# SPI0 register map
Vendor: Texas Instruments
Peripheral module from a debugger description file (folder 66AK2G0x_66AK2G1x).
Registers are 32-bit, access per field, reset 0x0 unless marked. A register's access mark holds for its fields unless they carry their own. Offsets are as the file gives them; lines under a group give offsets from that group; [hi:lo] are bit positions; {n}, {i} and the like mark numbered series; 'fields as' and 'values as' point back to an identical list; <NAME> marks a mode.

## SPI0
0x00 SPIGCR0
  [0] RESET rw — Reset bit for the module. This bit needs to be set to 1 before any operation on SPI can be done.
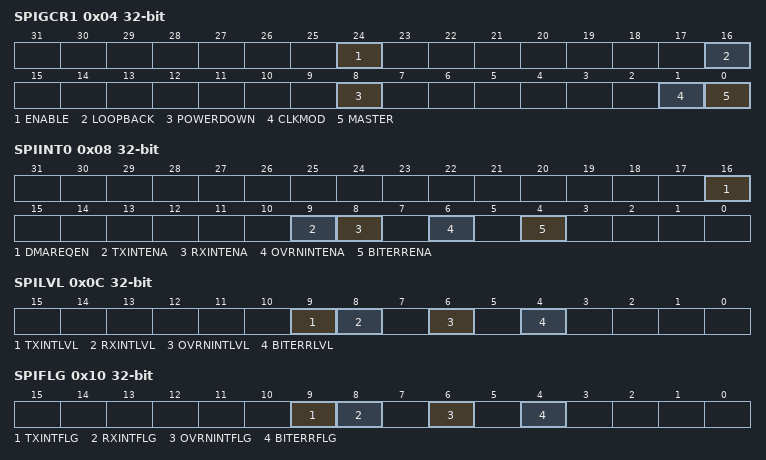
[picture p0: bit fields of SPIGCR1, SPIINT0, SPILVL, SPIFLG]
0x04 SPIGCR1
  [24] ENABLE rw — SPI enable. This bit enables the SPI transfers. The other SPI configuration registers except SPIINT0[16] DMAREQEN bit should be configured before writing 1 to this bit. This will prevent the SPI from responding to bus operations erroneously while it is in the process of being configured. The SPIINT0[16] DMAREQEN bit should be enabled after setting SPIGCR1[24] ENABLE bit. If SPIINT0[16] DMAREQEN bit is enabled before setting SPIGCR1[24] ENABLE bit then the first DMA request that occurs before the SPI is ready for data transfer may get dropped. When
  [16] LOOPBACK rw — Internal loop-back test mode. The internal self-test option can be enabled by setting this bit. If the SPIm_SIMO and SPIm_SOMI pins are configured with SPI functionality, then the SPIm_SIMO pin is internally connected to the SPIm_SOMI pin. The transmit data is looped back as receive data and is stored in the receive field of the concerned buffer. Externally, during loop-back operation, the SPIm_CLK pin outputs an inactive value, SPIm_SIMO and SPIm_SOMI pins remain in high-impedance state. The SPI has to be initialized in master mode before the loop-back can be selected. If the SPI is initialized in slave mode or a data transfer is ongoing, errors may result.
  [8] POWERDOWN rw — When active, the SPI state machine enters a power-down state.
  [1] CLKMOD rw — Clock mode. Selects either an internal or external clock source. This bit also determines the I/O direction of the chip select (SPIm_SCSnx) pins in functional mode.
  [0] MASTER rw — SPIm_SIMO/SPIm_SOMI pin direction determination. Determines the direction of the SPIm_SIMO and SPIm_SOMI pins. This bit determines whether the SPI is in Master mode or Slave mode.
0x08 SPIINT0
  [16] DMAREQEN rw — DMA request enable. Enables the DMA request signal to be generated for both receive and transmit channels. Set SPIINT0[16] DMAREQEN bit only after setting the SPIGCR1[24] ENABLE bit to 1.
  [9] TXINTENA rw — An interrupt is to be generated every time data is written to the shift register, so that a new data can be written to TXBUF. Setting this bit will generate an interrupt if theSPIFLG[9] TXINTFLG bit is set to 1.
  [8] RXINTENA rw — Receive interrupt enable. An interrupt is to be generated when the SPIFLG[8] RXINTFLG bit is set.
  [6] OVRNINTENA rw — Overrun interrupt enable. An interrupt is to be generated when the SPIFLG[6] OVRNINTFLG bit is set.
  [4] BITERRENA rw — Enables interrupt on bit error. An interrupt is to be generated when the SPIFLG[4] BITERRFLG bit is set.
0x0C SPILVL
  [9] TXINTLVL rw — Transmit interrupt level.
  [8] RXINTLVL rw — Receive interrupt level.
  [6] OVRNINTLVL rw — Receive overrun interrupt level.
  [4] BITERRLVL rw — Bit error interrupt level.
0x10 SPIFLG access not given
  [9] TXINTFLG ro — Transmitter empty interrupt flag. Serves as an interrupt flag indicating that the transmit buffer (TXBUF) is empty and a new data can be written to it. This flag is set when a data is copied to the shift register either directly or from the TXBUF register. This bit is cleared by one of following ways:
  [8] RXINTFLG — Receiver full interrupt flag. This flag is set when a word is received and copied into the buffer register (SPIBUF). This bit is cleared under the following ways: (access RW1C)
  [6] OVRNINTFLG — Receiver overrun flag. The bit is set when a receive operation completes before the previous character has been read from the receive buffer. The bit indicates that the last received character has been overwritten and therefore lost. This bit is cleared under the following conditions: (access RW1C)
  [4] BITERRFLG — This bit is set when a mismatch of internal transmit data and transmitted data is detected. The SPI samples the signal of the transmit pin (master: SPIm_SIMO, slave: SPIm_SOMI) at the receive point (half clock cycle after transmit point). If the sampled value differs from the transmitted value a bit error is detected and the flag is set. A possible reason for a bit error can be a too high bit rate/capacitive load or another master/slave trying to transmit at the same time. This flag can be cleared by one of the following ways: (access RW1C)
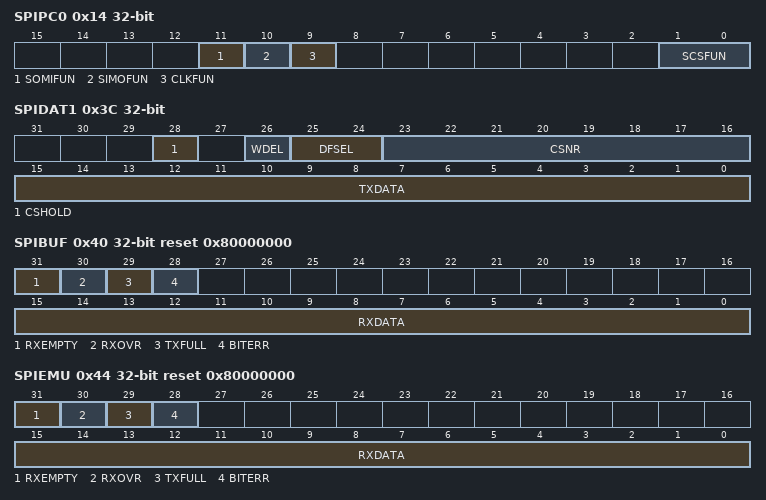
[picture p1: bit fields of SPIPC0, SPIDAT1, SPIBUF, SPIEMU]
0x14 SPIPC0
  [11] SOMIFUN rw — Slave out, master in pin function. This bit determines whether the SPIm_SOMI pin is Reserved or a SPI functional pin.
  [10] SIMOFUN rw — Slave in, master out pin function. This bit determines whether the SPIm_SIMO pin is Reserved or a SPI functional pin.
  [9] CLKFUN rw — SPI clock pin function. This bit determines whether the SPIm_CLK pin is Reserved or a SPI functional pin.
  [1:0] SCSFUN rw — SPI chip select pin function. The bit in this field determines whether the SPIm_SCSnx pin is Reserved or a SPI functional pin. For more information about supported number of the chip select pins, see , SPI Overview.
0x38 SPIDAT0
  [15:0] TXDATA rw — SPI transmit data (value = 0-FFFFh). When written, these bits will be copied to the shift register if it is empty. If the shift register is not empty, the TXBUF will hold the written values. SPIGCR1[24] ENABLE bit must be set to 1 before this register can be written to. Writing a 0 to the SPIGCR1[24] ENABLE bit forces the SPIDAT0[15-0] TXDATA field to 0.
0x3C SPIDAT1
  [28] CSHOLD rw — Chip select hold mode. The SPIDAT1[28] CSHOLD bit is supported in master mode only. In slave mode, this bit is ignored. SPIDAT1[28] CSHOLD bit defines the behavior of the chip select lines at the end of a data transfer.
  [26] WDEL rw — Enable the delay counter at the end of the current transaction. The SPIDAT1[26] WDEL bit is supported in master mode only. In slave mode, this bit is ignored.
  [25:24] DFSEL rw — Data word format select:
  [23:16] CSNR rw — Chip select number (value = 0-FFh). The SPIDAT1[23-16] CSNR field defines the chip select that will be activated during the data transfer. In slave mode, this field must be written as 00h; in master mode, the value of this field is driven on the chip select pins. Bits [23-18] are not used. Bits [17-16] are put out on SPIm_SCSn[1-0] during a transfer. For more information about supported number of the chip select pins, see , SPI Overview.
  [15:0] TXDATA rw — Transfer data (value = 0-FFFFh). When written, these bits will be copied to the shift register if it is empty. If the shift register is not empty, the TXBUF will hold the written values.
0x40 SPIBUF access not given reset 0x80000000
  [31] RXEMPTY — Receive data buffer empty. When the host reads the SPIBUF field or the whole SPIBUF register, this will automatically set the SPIBUF[31] RXEMPTY bit. When a data transfer is completed, the received data is copied into SPIBUF register, the SPIBUF[31] RXEMPTY bit is cleared. This flag is set to 1 under following conditions: Write-clearing the (access RS)
  [30] RXOVR — Receive data buffer overrun. When a data transfer is completed and the received data is copied into the RXBUF while it is already full, SPIBUF[30] RXOVR bit is set. An overrun always occurs to the RXBUF, and SPIBUF register contents never get overwritten until after it is read by the CPU/DMA. Reading (access RC)
  [29] TXFULL ro — Transmit data buffer full. This flag is a read-only flag. Writing into SPIDAT0 or SPIDAT1 field while the TX shift register is full will automatically set the SPIBUF[29] TXFULL bit. Once the data is copied to the shift register, the SPIBUF[29] TXFULL bit will be cleared. Writing to the SPIDAT0/SPIDAT1 register when both TXBUF and the TX shift register are empty does not set the SPIBUF[29] TXFULL bit.
  [28] BITERR — Bit error. There was a mismatch of internal transmit data and transmitted data. The SPI samples the signal of the transmit pin (master: SIMO, slave: SOMI) at the receive point (half clock cycle after transmit point). If the sampled value differs from the transmitted value, a bit error is detected and the flag BITERR is set. A possible reason for a bit error can be noise, a too-high bit rate/capacitive load, or another master/slave trying to transmit at the same time. (access RC)
  [15:0] RXDATA ro — SPI receive data (value = 0-FFFFh). This is the received data, transferred from the receive shift-register at the end of a transfer completion. Irrespective of the programmed character length and the direction of shifting, the received data is stored right-justified in the register.
0x44 SPIEMU ro reset 0x80000000
  [31] RXEMPTY — Receive data buffer empty.
  [30] RXOVR — Receive data buffer overrun.
  [29] TXFULL — Transmit data buffer full.
  [28] BITERR — Mismatch of internal transmit data and transmitted data.
  [15:0] RXDATA — SPI receive data (value = 0-FFFFh). SPI emulation is a mirror of the SPIBUF register. The only difference between SPIEMU and SPIBUF registers is that a read from SPIEMU register does not clear any of the status flags.
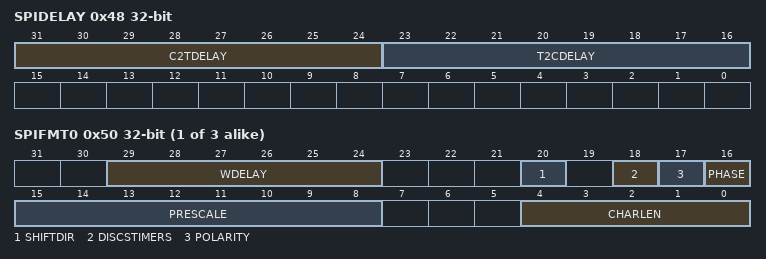
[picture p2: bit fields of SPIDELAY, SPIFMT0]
0x48 SPIDELAY
  [31:24] C2TDELAY rw — Chip-select-active-to-transmit-start delay (value = 0-FFh).SPIDELAY[31-24] C2TDELAY bit is used in master mode only. It defines a setup time for the slave device that delays the data transmission from the chip select active edge by a multiple of SPI module clock cycles. C2TDELAY can be configured between 2 and 257 SPI module clock cycles (See ). The setup time value is calculated as follows: t When the chip select signal becomes active, the slave has to prepare for data transfer within 320 ns.
  [23:16] T2CDELAY rw — Transmit-end-to-chip-select-inactive delay (value = 0-FFh).SPIDELAY[23-16] T2CDELAY is used in master mode only. It defines a hold time for the slave device that delays the chip select deactivation by a multiple of SPI module clock cycles after the last bit is transferred. T2CDELAY can be configured between 2 and 256 SPI module clock cycles (See ). The hold time value is calculated as follows: t Note: If T2CDELAY = 0, then t After the last data bit (or parity bit) is being transferred the chip select signal is held active for 160 ns.
0x4C SPIDEF reset 0x1
  [1:0] CSDEF rw — Chip Select Default pattern. In master mode, the bit in this field determines the SPIm_SCSnx pin state when no transmissions are currently performed. It allows the user to set a chip select pattern which deselects all the SPI slaves. For more information about supported number of the chip select pins, see , SPI Overview.
{0x50+4i} SPIFMT{i} (i=0..2)
  [29:24] WDELAY rw — Delay in between transmissions. Idle time that will be applied at the end of the current transmission if the SPIDAT1[26] WDEL bit is set in the current buffer. The delay to be applied is equal to: WDELAY × P P
  [20] SHIFTDIR rw — Shift direction.
  [18] DISCSTIMERS rw — Disable chip select timers for this format register. The C2TDELAY and T2CDELAY timers are by default enabled for all the data format registers. Using this bit, these timers can be disabled for a particular data format if not required. When a master is handling multiple slaves, with varied set-up hold requirement, the application can selectively choose to include or not include the chip select delay timers for any slaves.
  [17] POLARITY rw — SPI clock polarity.
  [16] PHASE rw — SPI clock delay.
  [15:8] PRESCALE rw — SPI prescaler (value = 0-FFh). It determines the bit transfer rate if the SPI is the network master and is directly derived from the SPI module clock. If the SPI is configured as slave, SPIFMTn[15-8] PRESCALE does not need to be configured. The clock rate can be calculated as: SPI clock frequency = SPI module clock/(PRESCALE + 1)
  [4:0] CHARLEN rw — SPI data word length (value = 0-1Fh). Legal values are 2h (data word length = 2 bit) to 10h (data word length = 16). Illegal values, such as 0 or 1Fh are not detected and their effect is indeterminate.
0x60 SPI_INTVEC0 ro
  [5:1] INTVECT0 — Interrupt vector for interrupt line INT0. SPI_INTVEC0[5-1] INTVECT0 field returns the vector of the pending interrupt at interrupt line INT0. If more than one interrupt is pending, SPI_INTVEC0[5-1] INTVECT0 field always references the highest priority interrupt source first. The interrupts available for SPI in the descending order of their priorities are as given below. The Vectors for each of these interrupts will be reflected on the The following are the SPI interrupt vectors for line INT0:
0x64 SPI_INTVEC1 ro
  [5:1] INTVECT1 — Interrupt vector for interrupt line INT1. SPI_INTVEC1[5-1] INTVECT1 field returns the vector of the pending interrupt at interrupt line INT1. If more than one interrupt is pending, SPI_INTVEC1[5-1] INTVECT1 field always references the highest priority interrupt source first. The interrupts available for SPI in the descending order of their priorities are as given below. The The following are the SPI interrupt vectors for line INT1:
0x1FC SPIREV ro reset 0x4A050300
  [31:0] REV — TI internal data. Identifies revision of peripheral.
